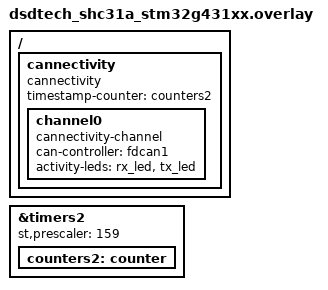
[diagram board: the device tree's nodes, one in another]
/*
 * SPDX-FileCopyrightText: Copyright (c) 2026 Base Power Company
 *
 * SPDX-License-Identifier: Apache-2.0
 */

#include "../app.overlay"

/ {
	cannectivity: cannectivity {
		compatible = "cannectivity";
		timestamp-counter = <&counters2>;

		channel0 {
			compatible = "cannectivity-channel";
			can-controller = <&fdcan1>;
			activity-leds = <&rx_led &tx_led>;
		};
	};
};

&timers2 {
	st,prescaler = <159>;
	counters2: counter {
		status = "okay";
	};
};
